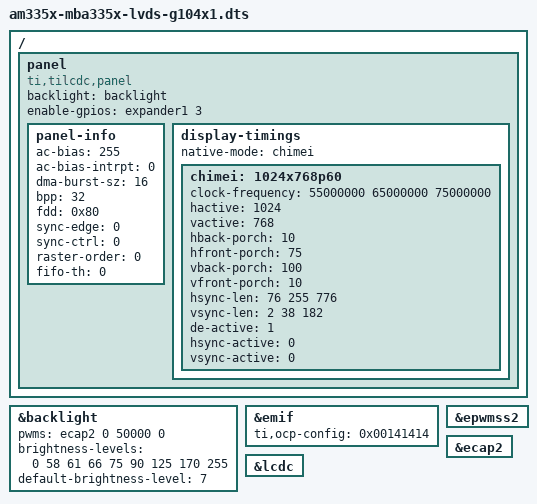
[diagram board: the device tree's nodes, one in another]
// SPDX-License-Identifier: GPL-2.0-only
/*
 * Copyright (c) 2014, 2021-2023 TQ-Systems GmbH <linux@ew.tq-group.com>,
 * D-82229 Seefeld, Germany.
 *
 * Based on:
 * Copyright (C) 2012 Texas Instruments Incorporated - http://www.ti.com/
 */
#include "am335x-mba335x.dts"
#include <dt-bindings/gpio/gpio.h>
#include <dt-bindings/interrupt-controller/irq.h>
#include <dt-bindings/pwm/pwm.h>

/ {
	panel {
		compatible = "ti,tilcdc,panel";
		backlight = <&backlight>;
		enable-gpios = <&expander1 3 GPIO_ACTIVE_HIGH>;

		panel-info {
			ac-bias           = <255>;
			ac-bias-intrpt    = <0>;
			dma-burst-sz      = <16>;
			bpp               = <32>;
			fdd               = <0x80>;
			sync-edge         = <0>;
			sync-ctrl         = <0>;
			raster-order      = <0>;
			fifo-th           = <0>;
		};

		display-timings {
			native-mode = <&chimei>;

			/* CHIMEI G104X1-L04 */
			chimei: 1024x768p60 {
				clock-frequency = <55000000 65000000 75000000>;
				hactive = <1024>;
				vactive = <768>;
				hback-porch = <10>;
				hfront-porch = <75>;
				vback-porch = <100>;
				vfront-porch = <10>;
				hsync-len = <76 255 776>;
				vsync-len = <2 38 182>;
				de-active = <1>;
				hsync-active = <0>;
				vsync-active = <0>;
			};
		};
	};
};

&backlight {
	pwms = <&ecap2 0 50000 0>;
	brightness-levels = <0 58 61 66 75 90 125 170 255>;
	default-brightness-level = <7>;
	status = "okay";
};

/*
 * See also:
 * https://source.denx.de/u-boot/u-boot/-/commit/8c17cbdf8a8023abdd0009af4dc9dbc0541b4a0f
 */
&emif {
	ti,ocp-config = <0x00141414>;
};

&epwmss2 {
	status = "okay";
};

&ecap2 {
	status = "okay";
};

&lcdc {
	status = "okay";
};
